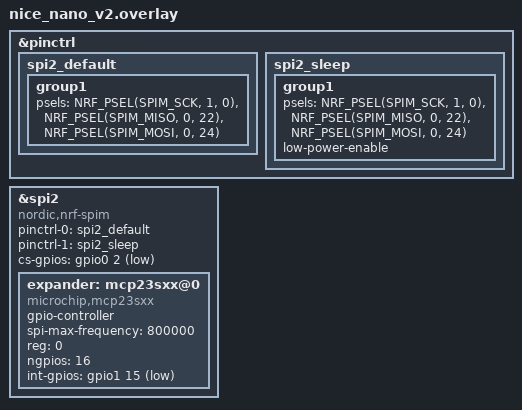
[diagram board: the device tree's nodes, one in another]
//#include <dt-bindings/led/led.h>

&pinctrl {
//    spi3_default: spi3_default {
//        group1 {
//            psels = <NRF_PSEL(SPIM_SCK, 0, 25)>,
//                <NRF_PSEL(SPIM_MOSI, 0, 11)>;
//        };
//    };
//
//    spi3_sleep: spi3_sleep {
//        group1 {
//            psels = <NRF_PSEL(SPIM_SCK, 0, 25)>,
//                <NRF_PSEL(SPIM_MOSI, 0, 11)>;
//            low-power-enable;
//        };
//    };
//
    spi2_default: spi2_default {
        group1 {
            psels = <NRF_PSEL(SPIM_SCK, 1, 0)>,
                <NRF_PSEL(SPIM_MISO, 0, 22)>,
                <NRF_PSEL(SPIM_MOSI, 0, 24)>;
        };
    };
    spi2_sleep: spi2_sleep {
        group1 {
            psels = <NRF_PSEL(SPIM_SCK, 1, 0)>,
                <NRF_PSEL(SPIM_MISO, 0, 22)>,
                <NRF_PSEL(SPIM_MOSI, 0, 24)>;
            low-power-enable;
        };
    };
};
//
//&spi3 {
//  compatible = "nordic,nrf-spim";
//  status = "okay";
//
//  pinctrl-0 = <&spi3_default>;
//  pinctrl-1 = <&spi3_sleep>;
//  pinctrl-names = "default", "sleep";
//
//  led_strip: ws2812@0 {
//    compatible = "worldsemi,ws2812-spi";
//
//    /* SPI */
//    reg = <0>; /* ignored, but necessary for SPI bindings */
//    spi-max-frequency = <4000000>;
//
//    /* WS2812 */
//    chain-length = <88>; /* number of LEDs */
//    spi-one-frame = <0x70>;
//    spi-zero-frame = <0x40>;
//    color-mapping = <LED_COLOR_ID_GREEN
//                          LED_COLOR_ID_RED
//                          LED_COLOR_ID_BLUE>;
//  };
//};

&spi2 {
    compatible = "nordic,nrf-spim";
    status = "okay";

    pinctrl-0 = <&spi2_default>;
    pinctrl-1 = <&spi2_sleep>;
    pinctrl-names = "default", "sleep";

    cs-gpios = <&gpio0 2 GPIO_ACTIVE_LOW>;
//                &gpio0 29 GPIO_ACTIVE_LOW>;
    //    &xiao_d 0 GPIO_ACTIVE_HIGH>;

    expander: mcp23sxx@0 {
        compatible = "microchip,mcp23sxx";
        status = "okay";
        gpio-controller;
        spi-max-frequency = <800000>;
        reg = <0>;
//        label = "MCP23S17";
        #gpio-cells = <2>;
        ngpios = <16>;
        int-gpios = <&gpio1 15 GPIO_ACTIVE_LOW>;

//        led_disable {
//            gpio-hog;
//            gpios = <45 GPIO_ACTIVE_HIGH>;
//            output-high;
//        };
    };
};

//&pro_micro_serial {
//    status = "disabled";
//};

